# R7KA8D2AD register map
Vendor: Renesas Electronics Corporation; Series: RA8; File version: 1.10.02
CPU: CM85 r0p2, little endian, MPU, FPU, VTOR, 4 interrupt priority bits, 96 interrupts
Registers are 32-bit, read-write, reset 0x0 unless marked. A register's access mark holds for its fields unless they carry their own. Offsets are from the block's base; [hi:lo] are bit positions; 'fields as' and 'values as' point back to an identical list.

## I3C (part 1 of 2) — I3C Bus Interface
Base 0x4035F000
0x00 PRTS reset 0x1 — Protocol Selection Register
  [0] PRTMD — Protocol Mode
    0=I3C protocol mode; 1=I2C protocol mode
0x10 CECTL — Clock Enable Control Resister
  [0] CLKE — Clock Enable
    0=Clock disable; 1=Clock enable
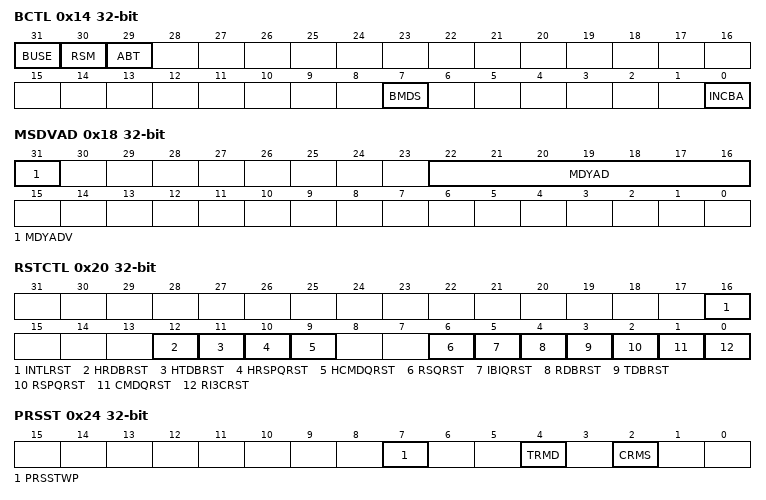
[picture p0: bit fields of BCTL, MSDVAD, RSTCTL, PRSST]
0x14 BCTL — Bus Control Register
  [31] BUSE — Bus Enable
    0=I3C bus operation is disabled; 1=I3C bus operation is enabled
  [30] RSM — Resume
    0=I3C is running; 1=I3C is suspended
  [29] ABT — Abort
    0=I3C is running; 1=I3C has aborted a transfer
  [7] BMDS — Bus Mode Selection
    0=Legacy inclusive Bus mode disabled; 1=Legacy inclusive (mix) Bus mode enabled
  [0] INCBA — Include I3C Broadcast Address
    0=Do not include I3C broadcast address for private transfers; 1=Include I3C broadcast address for private transfers
0x18 MSDVAD — Master Device Address Register
  [31] MDYADV — Master Dynamic Address Valid
    0=The master dynamic address field is not valid; 1=The master dynamic address field is valid
  [22:16] MDYAD — Master Dynamic Address
0x20 RSTCTL — Reset Control Register
  [16] INTLRST — Internal Software Reset
    0=Releases of some registers and internal state; 1=Resets of some registers and internal state
  [12] HRDBRST — High Priority Rx Data Buffer Software Reset
    0=The High Priority Rx Data buffers in I3C is not flushed; 1=The High Priority Rx Data buffers in I3C is flushed
  [11] HTDBRST — High Priority Tx Data Buffer Software Reset
    0=The High Priority Tx Data buffers in I3C is not flushed; 1=The High Priority Tx Data buffers in I3C is flushed
  [10] HRSPQRST — High Priority Response Queue Software Reset
    0=The High Priority Response Queues in I3C is not flushed; 1=The High Priority Response Queues in I3C is flushed
  [9] HCMDQRST — High Priority Command Queue Software Reset
    0=The High Priority Command Queues in I3C is not flushed; 1=The High Priority Command Queues in I3C is flushed
  [6] RSQRST — Normal Receive Status Queue Software Reset
    0=The Normal Receive Status Queue in I3C is not flushed; 1=The Normal Receive Status Queue in I3C is flushed
  [5] IBIQRST — Normal IBI Queue Software Reset
    0=The Normal IBI Queues in I3C is not flushed; 1=The Normal IBI Queues in I3C is flushed
  [4] RDBRST — Normal Rx Data Buffer Software Reset
    0=The Normal Rx Data buffers in I3C is not flushed; 1=The Normal Rx Data buffers in I3C is flushed
  [3] TDBRST — Normal Tx Data Buffer Software Reset
    0=The Normal Tx Data buffers in I3C is not flushed; 1=The Normal Tx Data buffers in I3C is flushed
  [2] RSPQRST — Normal Response Queue Software Reset
    0=The Normal Response Queues in I3C is not flushed; 1=The Normal Response Queues in I3C is flushed
  [1] CMDQRST — Normal Command Queue Software Reset
    0=The Normal Command Queues in I3C is not flushed; 1=The Normal Command Queues in I3C is flushed
  [0] RI3CRST — I3C Software Reset
    0=Release I3C reset; 1=Initiate I3C reset
0x24 PRSST — Present State Register
  [7] PRSSTWP wo — Present State Write Protect
    0=CRMS bit is protected; 1=CRMS bit can be written when writing simultaneously with the value of the target bit
  [4] TRMD ro — Transmit/Receive Mode
    0=Receive mode; 1=Transmit mode
  [2] CRMS — Current Master
    0=The Master is not the Current Master, and must request and acquire bus ownership before initiating any transfer; 1=The Master is the Current Master, and as a result can initiate transfers
0x30 INST — Internal Status Register
  [10] INEF — Internal Error Flag
    0=I3C Internal Error has not detected; 1=I3C Internal Error has detected
0x34 INSTE — Internal Status Enable Register
  [10] INEE — Internal Error Enable
    0=Disable INST.INEF; 1=Enable INST.INEF
0x38 INIE — Internal Interrupt Enable Register
  [10] INEIE — Internal Error Interrupt Enable
    0=Disables Non-recoverable Internal Error Interrupt Signal; 1=Enables Non-recoverable Internal Error Interrupt Signal
0x3C INSTFC wo — Internal Status Force Register
  [10] INEFC — Internal Error Force
    0=Not force a specific interrupt; 1=Force a specific interrupt
0x44 DVCT ro — Device Characteristic Table Register
  [23:19] IDX — DCT Table Index
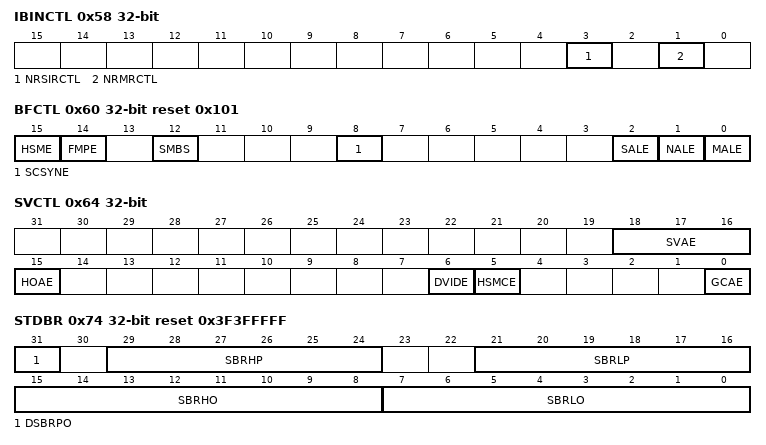
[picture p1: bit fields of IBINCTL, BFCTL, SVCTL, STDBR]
0x58 IBINCTL — IBI Notify Control Register
  [3] NRSIRCTL — Notify Rejected Slave Interrupt Request Control
    0=Do not pass rejected IBI Status to the Normal IBI Queue, if the incoming SIR is NACKed and is auto-disabled based on DVSIRRJ field in relevant DAT entry; 1=Pass rejected IBI Status to the Normal IBI Queue, if the incoming SIR is NACKed and is auto-disabled based on DVSIRRJ field in relevant DAT entry
  [1] NRMRCTL — Notify Rejected Master Request Control
    0=Do not pass rejected IBI Status to the Normal IBI Queue, if the incoming Master Request is NACKed and is auto-disabled based on DVMRRJ field in relevant DAT entry; 1=Pass rejected IBI Status to the Normal IBI Queue if the incoming Master Request is NACKed and is auto-disabled based on DVMRRJ field in relevant DAT entry
0x60 BFCTL reset 0x101 — Bus Function Control Register
  [15] HSME — High Speed Mode Enable
    0=Disable High Speed Mode; 1=Enable High Speed Mode
  [14] FMPE — Fast-mode Plus Enable
    0=No Fm+ slope control circuit uses for the I3C_SCL pin and I3C_SDA pin. (n = 0); 1=An Fm+ slope control circuit uses for the I3C_SCL pin and I3C_SDA pin. (n = 0)
  [12] SMBS — SMBus/I2C Bus Selection
    0=The I2C bus select; 1=The SMBus select
  [8] SCSYNE — SCL Synchronous Circuit Enable
    0=No SCL synchronous circuit uses; 1=An SCL synchronous circuit uses
  [2] SALE — Slave Arbitration-Lost Detection Enable
    0=Slave arbitration-lost detection disables; 1=Slave arbitration-lost detection enables
  [1] NALE — NACK Transmission Arbitration-Lost Detection Enable
    0=NACK transmission arbitration-lost detection disables; 1=NACK transmission arbitration-lost detection enables
  [0] MALE — Master Arbitration-Lost Detection Enable
    0=Master arbitration-lost detection disables. Disables the arbitration-lost detection function and does not clear the CRMS and TRMD bits in PRSST automatically when arbitration is lost.; 1=Master arbitration-lost detection enables. Enables the arbitration-lost detection function and clears the CRMS and TRMD bits in PRSST automatically when arbitration is lost.
0x64 SVCTL — Slave Control Register
  [18:16] SVAE — Slave Address Enable n ( n = 0 to 2 )
    0=Slave n disables; 1=Slave n enables
  [15] HOAE — Host Address Enable
    0=Host address detection disables; 1=Host address detection enables
  [6] DVIDE — Device-ID Address Enable
    0=Device-ID address detection disables; 1=Device-ID address detection enables
  [5] HSMCE — Hs-mode Master Code Enable
    0=Hs-mode Master Code Detection disables; 1=Hs-mode Master Code Detection enables
  [0] GCAE — General Call Address Enable
    0=General call address detection disables; 1=General call address detection enables
0x70 REFCKCTL — Reference Clock Control Register
  [2:0] IREFCKS — Internal Reference Clock Selection
    0=TCLK/1 clock; 1=TCLK/2 clock; 2=TCLK/4 clock; 3=TCLK/8 clock; 4=TCLK/16 clock; 5=TCLK/32 clock; 6=TCLK/64 clock; 7=TCLK/128 clock
0x74 STDBR reset 0x3F3FFFFF — Standard Bit Rate Register
  [31] DSBRPO — Double the Standard Bit Rate Period for Open-Drain
    0=The time period set for SBRHO[7:0] and SBRLO[7:0] is not doubled; 1=The time period set for SBRHO[7:0] and SBRLO[7:0] is doubled
  [29:24] SBRHP — Standard Bit Rate High-Level Period Push-Pull
  [21:16] SBRLP — Standard Bit Rate Low-level Period Push-Pull
  [15:8] SBRHO — Standard Bit Rate High-Level Period Open-Drain
  [7:0] SBRLO — Standard Bit Rate Low-Level Period Open-Drain
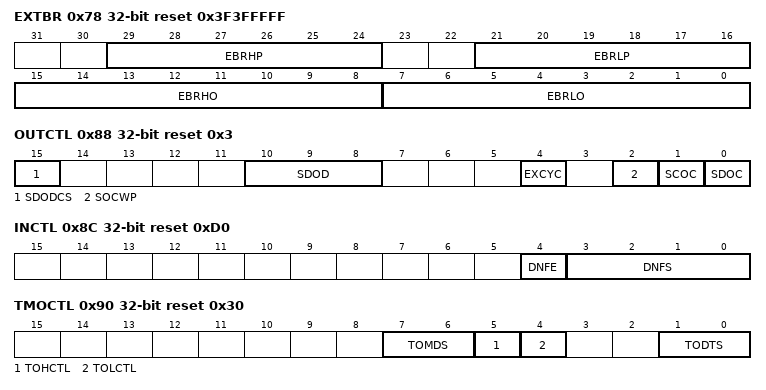
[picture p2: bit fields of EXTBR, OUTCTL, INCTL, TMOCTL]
0x78 EXTBR reset 0x3F3FFFFF — Extended Bit Rate Register
  [29:24] EBRHP — Extended Bit Rate High-Level Period Push-Pull
  [21:16] EBRLP — Extended Bit Rate Low-Level Period Push-Pull
  [15:8] EBRHO — Extended Bit Rate High-Level Period Open-Drain
  [7:0] EBRLO — Extended Bit Rate Low-Level Period Open-Drain
0x7C BFRECDT — Bus Free Condition Detection Time Register
  [8:0] FRECYC — Bus Free Condition Detection Cycle
0x80 BAVLCDT — Bus Available Condition Detection Time Register
  [8:0] AVLCYC — Bus Available Condition Detection Cycle
0x84 BIDLCDT — Bus Idle Condition Detection Time Register
  [17:0] IDLCYC — Bus Idle Condition Detection Cycle
0x88 OUTCTL reset 0x3 — Output Control Register
  [15] SDODCS — SDA Output Delay Clock Source Selection
    0=The internal reference clock (I3Cφ) is selected as the clock source of the SDA output delay counter; 1=The internal reference clock divided by 2 (I3Cφ/2) is selected as the clock source of the SDA output delay counter
  [10:8] SDOD — SDA Output Delay
    0=No output delay; 1=1 I3Cφ cycle (When OUTCTL.SDODCS = 0 (I3Cφ)) 1 or 2 I3Cφ cycles (When OUTCTL.SDODCS = 1 (I3Cφ/2)); 2=2 I3Cφ cycles (When OUTCTL.SDODCS = 0 (I3Cφ)) 3 or 4 I3Cφ cycles (When OUTCTL.SDODCS = 1 (I3Cφ/2)); 3=3 I3Cφ cycles (When OUTCTL.SDODCS = 0 (I3Cφ)) 5 or 6 I3Cφ cycles (When OUTCTL.SDODCS = 1 (I3Cφ/2)); 4=4 I3Cφ cycles (When OUTCTL.SDODCS = 0 (I3Cφ)) 7 or 8 I3Cφ cycles (When OUTCTL.SDODCS = 1 (I3Cφ/2)); 5=5 I3Cφ cycles (When OUTCTL.SDODCS = 0 (I3Cφ)) 9 or 10 I3Cφ cycles (When OUTCTL.SDODCS = 1 (I3Cφ/2)); 6=6 I3Cφ cycles (When OUTCTL.SDODCS = 0 (I3Cφ)) 11 or 12 I3Cφ cycles (When OUTCTL.SDODCS = 1 (I3Cφ/2)); 7=7 I3Cφ cycles (When OUTCTL.SDODCS = 0 (I3Cφ)) 13 or 14 I3Cφ cycles (When OUTCTL.SDODCS = 1 (I3Cφ/2))
  [4] EXCYC — Extra SCL Clock Cycle Output
    0=Does not output an extra SCL clock cycle (default); 1=Outputs an extra SCL clock cycle
  [2] SOCWP wo — SCL/SDA Output Control Write Protect
    0=Bits SCOC and SDOC are protected; 1=Bits SCOC and SDOC can be written (When writing simultaneously with the value of the target bit). This bit is read as 0.
  [1] SCOC — SCL Output Control
    0=I3C drives the I3C_SCL pin low; 1=I3C releases the I3C_SCL pin
  [0] SDOC — SDA Output Control
    0=I3C drives the I3C_SDA pin low; 1=I3C releases the I3C_SDA pin
0x8C INCTL reset 0xD0 — Input Control Register
  [4] DNFE — Digital Noise Filter Circuit Enable
    0=No digital noise filter circuit is used; 1=A digital noise filter circuit is used
  [3:0] DNFS — Digital Noise Filter Stage Selection
0x90 TMOCTL reset 0x30 — Timeout Control Register
  [7:6] TOMDS — Timeout Operation Mode Selection
    0=Timeout is detected during the following conditions: The bus is busy (BCST.BFREF = 0) in master mode.I3C’s own slave address is detected and the bus is busy in slave mode.The bus is free (BCST.BFREF = 1) while generation of a START condition is requested (CNDCTL.STCND = 1); 1=Timeout is detected while the bus is busy; 2=Timeout is detected while the bus is free; 3=Setting prohibited
  [5] TOHCTL — Timeout H Count Control
    0=Count is disabled while the I3C_SCL line is at a high level; 1=Count is enabled while the I3C_SCL line is at a high level
  [4] TOLCTL — Timeout L Count Control
    0=Count is disabled while the I3C_SCL line is at a low level; 1=Count is enabled while the I3C_SCL line is at a low level
  [1:0] TODTS — Timeout Detection Time Selection
    0=16bit-timeout; 1=14bit-timeout; 2=8bit-timeout; 3=6bit-timeout
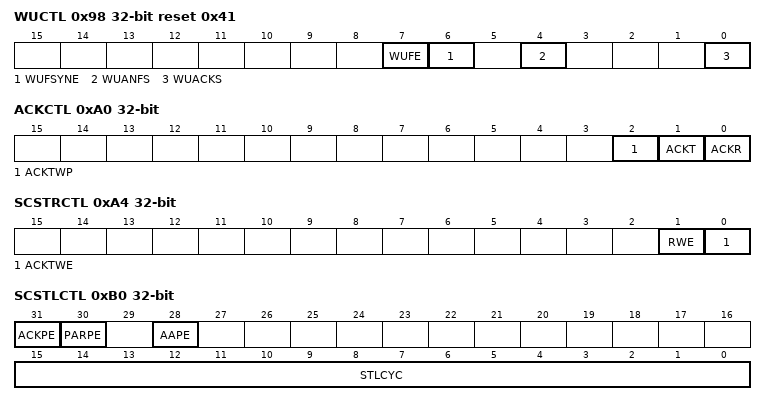
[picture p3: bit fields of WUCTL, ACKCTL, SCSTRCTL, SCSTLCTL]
0x98 WUCTL reset 0x41 — Wake Up Unit Control Register
  [7] WUFE — Wake-Up function Enable
    0=Wake-up function disables; 1=Wake-up function enables
  [6] WUFSYNE — Wake-Up function PCLK Synchronous Enable
    0=I3C asynchronous circuit enable; 1=I3C synchronous circuit enable
  [4] WUANFS — Wake-Up Analog Noise Filter Selection
    0=Do not add the Wake Up analog filter; 1=Add the Wake Up analog filter
  [0] WUACKS — Wake-Up Acknowledge Selection
0xA0 ACKCTL — Acknowledge Control Register
  [2] ACKTWP wo — ACKT Write Protect
    0=The ACKT bit are protected; 1=The ACKT bit can be written (when writing simultaneously with the value of the target bit). This bit is read as 0.
  [1] ACKT — Acknowledge Transmission
    0=A 0 is sent as the acknowledge bit (ACK transmission); 1=A 1 is sent as the acknowledge bit (NACK transmission)
  [0] ACKR ro — Acknowledge Reception
    0=A 0 is received as the acknowledge bit (ACK reception); 1=A 1 is received as the acknowledge bit (NACK reception)
0xA4 SCSTRCTL — SCL Stretch Control Register
  [1] RWE — Receive Wait Enable
    0=No WAIT (The period between ninth clock cycle and first clock cycle is not held low.); 1=WAIT (The period between ninth clock cycle and first clock cycle is held low.) Low-hold is released by reading NTDTBP0
  [0] ACKTWE — Acknowledge Transmission Wait Enable
    0=NTST.RDBFF0 is set at the rising edge of the ninth SCL clock cycle. (The I3C_SCL line is not held low at the falling edge of the eighth clock cycle.); 1=NTST.RDBFF0 is set at the rising edge of the eighth SCL clock cycle. (The I3C_SCL line is held low at the falling edge of the eighth clock cycle.) Low-hold is released by writing a value to the ACKCTL.ACKT bit.
0xB0 SCSTLCTL — SCL Stalling Control Register
  [31] ACKPE — ACK phase Enable
    0=Does not stall the SCL clock during the ACK/NACK phase; 1=Stall the SCL clock during the ACK/NACK phase
  [30] PARPE — Parity Phase Enable
    0=Does not stall the SCL clock during the parity bit period; 1=Stall the SCL clock during the parity bit period
  [28] AAPE — Assigned Address Phase Enable
    0=Does not stall the SCL clock during the address assignment phase; 1=Stall the SCL clock during address assignment phase
  [15:0] STLCYC — Stalling Cycle
0xC0 SVTDLG0 — Slave Transfer Data Length Register 0
  [31:16] STDLG — Slave Transfer Data Length
0x120 STCTL — Synchronous Timing Control Register
  [0] STOE — Synchronous Timing output Enable
    0=Disable; 1=Enable
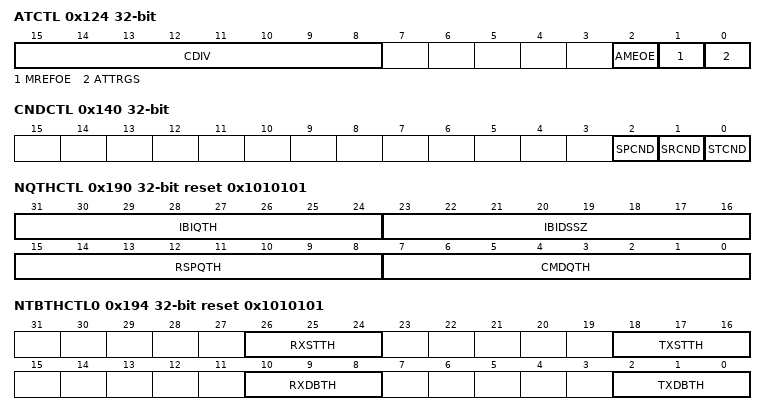
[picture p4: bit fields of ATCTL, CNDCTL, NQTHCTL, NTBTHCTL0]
0x124 ATCTL — Asynchronous Timing Control Register
  [15:8] CDIV — TCLK Counter Divide Setting
  [2] AMEOE — Additional Master-initiated bus Event Output Enable
    0=Disable; 1=Enable
  [1] MREFOE — MREF Output Enable (Capture Event / Counter Overflow)
    0=Disable; 1=Enable
  [0] ATTRGS — Asynchronous Timing Trigger Select
    0=Software trigger; 1=Hardware trigger
0x128 ATTRG — Asynchronous Timing Trigger Register
  [0] ATSTRG wo — Asynchronous Timing Software Trigger
    0=Do nothing; 1=Software trigger (one-shot pulse) output This bit is always read as 0
0x12C ATCCNTE — Asynchronous Timing Control Counter Enable Register
  [0] ATCE — Asynchronous Timing Counter Enable for MREF, MC2, SC1, SC2.
    0=Disable; 1=Enable
0x140 CNDCTL — Condition Control Register
  [2] SPCND — STOP (P) Condition Issuance
    0=Does not request to issue a STOP condition; 1=Requests to issue a STOP condition
  [1] SRCND — Repeated START (Sr) Condition Issuance
    0=Does not request to issue a Repeated START condition; 1=Requests to issue a Repeated START condition
  [0] STCND — START (S) Condition Issuance
    0=Does not request to issue a START condition; 1=Requests to issue a START condition
0x150 NCMDQP wo — Normal Command Queue Port Register
0x154 NRSPQP ro — Normal Response Queue Port Register
0x158 NTDTBP0 — Normal Transfer Data Buffer Port Register 0
0x158 NTDTBP0_BY 8-bit (alternate view of NTDTBP0) — Normal Transfer Data Buffer Port Register 0
0x17C NIBIQP — Normal IBI Queue Port Register
0x180 NRSQP ro — Normal Receive Status Queue Port Register
0x184 HCMDQP wo — High Priority Command Queue Port Register
0x188 HRSPQP ro — High Priority Response Queue Port Register
0x18C HTDTBP — High Priority Transfer Data Buffer Port Register
0x190 NQTHCTL reset 0x1010101 — Normal Queue Threshold Control Register
  [31:24] IBIQTH — Normal IBI Queue Threshold
    0=I3C Protocol mode (Master): Interrupt is generated when the Outstanding IBI Status count is 1 or more. I3C Protocol mode (Slave): Interrupt is issued when IBI Data Buffer is completely empty.; other=Others (I3C Protocol mode (Master): Interrupt is generated when the Outstanding IBI Status count is N + 1 or more. (N = CMDQTH[7:0]) I3C Protocol mode (Slave): Interrupt is issued when IBI Data Buffer contains N empties.)
  [23:16] IBIDSSZ — Normal IBI Data Segment Size
  [15:8] RSPQTH — Normal Response Queue Threshold
    0=Interrupt is issued when Normal Response Queue contains 1 entry (DWORD); other=Others (Interrupt is triggered when Normal Response Queue contains N+1 entries (DWORD). (N = CMDQTH[7:0]))
  [7:0] CMDQTH — Normal Command Queue Threshold
    0=Interrupt is issued when Normal Command Queue is completely empty; other=Others (Interrupt is issued when Normal Command Queue contains N empties. (N = CMDQTH[7:0]))
0x194 NTBTHCTL0 reset 0x1010101 — Normal Transfer Data Buffer Threshold Control Register 0
  [26:24] RXSTTH — Normal Rx Start Threshold
    0=Wait for 2 empty DWORDs; 1=Wait for 4 empty DWORDs; 2=Wait for 8 empty DWORDs; 3=Wait for 16 empty DWORDs; other=Others (Setting prohibited)
  [18:16] TXSTTH — Normal Tx Start Threshold
    0=Wait for 2 entry DWORDs; 1=Wait for 4 entry DWORDs; 2=Wait for 8 entry DWORDs; 3=Wait for 16 entry DWORDs; other=Others (Setting prohibited)
  [10:8] RXDBTH — Normal Rx Data Buffer Threshold
    0=Interrupt triggers at 2 Rx Buffer entries, DWORDs; 1=Interrupt triggers at 4 Rx Buffer entries, DWORDs; 2=Interrupt triggers at 8 Rx Buffer entries, DWORDs; 3=Interrupt triggers at 16 Rx Buffer entries, DWORDs; other=Others (Setting prohibited)
  [2:0] TXDBTH — Normal Tx Data Buffer Threshold
    0=Interrupt triggers at 2 Tx Buffer empties, DWORDs; 1=Interrupt triggers at 4 Tx Buffer empties, DWORDs; 2=Interrupt triggers at 8 Tx Buffer empties, DWORDs; 3=Interrupt triggers at 16 Tx Buffer empties, DWORDs; other=Others (Setting prohibited)
0x1C0 NRQTHCTL reset 0x1 — Normal Receive Status Queue Threshold Control Register
  [7:0] RSQTH — Normal Receive Status Queue Threshold
    0=Interrupt is issued when Normal Receive Status Queue contains 1 entry (DWORD); other=Others (Interrupt is triggered when Normal Receive Status Queue contains N+1 entries (DWORD). (N = RSQTH[7:0]))
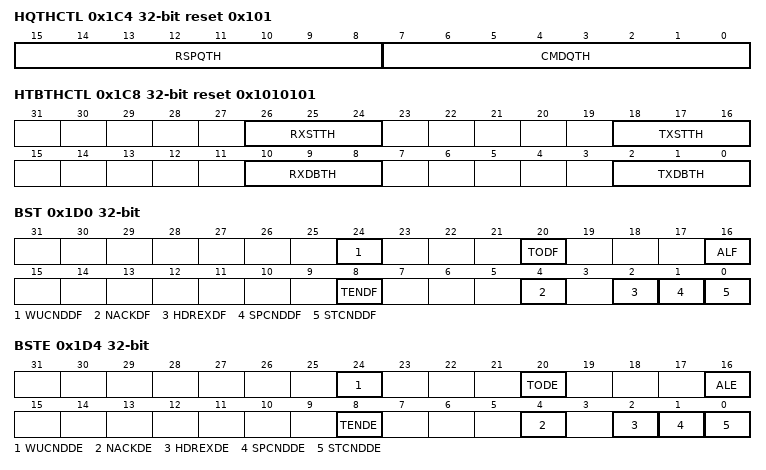
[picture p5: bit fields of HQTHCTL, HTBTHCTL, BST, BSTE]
0x1C4 HQTHCTL reset 0x101 — High Priority Queue Threshold Control Register
  [15:8] RSPQTH — High Priority Response Queue Threshold
    0=Interrupt is issued when High Priority Response Queue contains 1 entry (DWORD); other=Others (Interrupt is triggered when High Priority Response Queue contains N+1 entries (DWORD). (N = RSPQTH[7:0]))
  [7:0] CMDQTH — High Priority Command Queue Threshold
    0=Interrupt is issued when High Priority Command Queue is completely empty; other=Others (Interrupt is issued when High Priority Command Queue contains N entries. (N = CMDQTH[7:0]))
0x1C8 HTBTHCTL reset 0x1010101 — High Priority Transfer Data Buffer Threshold Control Register
  [26:24] RXSTTH — High Priority Rx Start Threshold
    0=Wait for 2 empty DWORDs; other=Others (Setting prohibited)
  [18:16] TXSTTH — High Priority Tx Start Threshold
    0=Wait for 2 entry DWORDs; other=Others (Setting prohibited)
  [10:8] RXDBTH — High Priority Rx Data Buffer Threshold
    0=Interrupt triggers at 2 High Priority Rx Buffer entries, DWORDs; other=Others (Setting prohibited)
  [2:0] TXDBTH — High Priority Tx Data Buffer Threshold
    0=Interrupt triggers at 2 High Priority Tx Buffer empties, DWORDs; other=Others (Setting prohibited)
0x1D0 BST — Bus Status Register
  [24] WUCNDDF — Wake-Up Condition Detection Flag
    0=Wake-Up is not detected; 1=Wake-Up is detected
  [20] TODF — Timeout Detection Flag
    0=Timeout is not detected; 1=Timeout is detected
  [16] ALF — Arbitration Lost Flag
    0=Arbitration is not lost; 1=Arbitration is lost
  [8] TENDF — Transmit End Flag
    0=Data is being transmitted; 1=Data has been transmitted
  [4] NACKDF — NACK Detection Flag
    0=NACK is not detected; 1=NACK is detected
  [2] HDREXDF — HDR Exit Pattern Detection Flag
    0=HDR Exit Pattern is not detected; 1=HDR Exit Pattern is detected
  [1] SPCNDDF — STOP Condition Detection Flag
    0=STOP condition is not detected; 1=STOP condition is detected
  [0] STCNDDF — START Condition Detection Flag
    0=START condition is not detected; 1=START condition is detected
0x1D4 BSTE — Bus Status Enable Register
  [24] WUCNDDE — Wake-up Condition Detection Enable
    0=Disables Wake-up Condition Detection Status logging; 1=Enables Wake-up Condition Detection Status logging
  [20] TODE — Timeout Detection Enable
    0=Disables Timeout Detection Interrupt Status logging; 1=Enables Timeout Detection Interrupt Status logging
  [16] ALE — Arbitration Lost Enable
    0=Disables Arbitration Lost Interrupt Status logging; 1=Enables Arbitration Lost Interrupt Status logging
  [8] TENDE — Transmit End Enable
    0=Disables Transmit End Interrupt Status logging; 1=Enables Transmit End Interrupt Status logging
  [4] NACKDE — NACK Detection Enable
    0=Disables NACK Detection Interrupt Status logging; 1=Enables NACK Detection Interrupt Status logging
  [2] HDREXDE — HDR Exit Pattern Detection Enable
    0=Disables HDR Exit Pattern Detection Interrupt Status logging; 1=Enables HDR Exit Pattern Detection Interrupt Status logging
  [1] SPCNDDE — STOP Condition Detection Enable
    0=Disables STOP condition Detection Interrupt Status logging; 1=Enables STOP condition Detection Interrupt Status logging
  [0] STCNDDE — START Condition Detection Enable
    0=Disables START condition Detection Interrupt Status logging; 1=Enables START condition Detection Interrupt Status logging
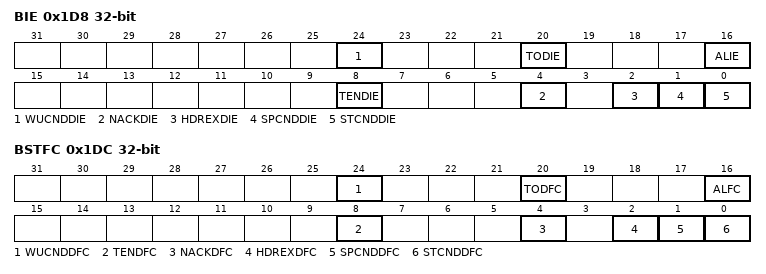
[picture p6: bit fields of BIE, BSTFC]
0x1D8 BIE — Bus Interrupt Enable Register
  [24] WUCNDDIE — Wake-Up Condition Detection Interrupt Enable
    0=Disables Wake-Up Condition Detection Interrupt Signal; 1=Enables Wake-Up Condition Detection Interrupt Signal
  [20] TODIE — Timeout Detection Interrupt Enable
    0=Disables Timeout Detection Interrupt Signal; 1=Enables Timeout Detection Interrupt Signal
  [16] ALIE — Arbitration Lost Interrupt Enable
    0=Disables Arbitration Lost Interrupt Signal; 1=Enables Arbitration Lost Interrupt Signal
  [8] TENDIE — Transmit End Interrupt Enable
    0=Disables Transmit End Interrupt Signal; 1=Enables Transmit End Interrupt Signal
  [4] NACKDIE — NACK Detection Interrupt Enable
    0=Disables NACK Detection Interrupt Signal; 1=Enables NACK Detection Interrupt Signal
  [2] HDREXDIE — HDR Exit Pattern Detection Interrupt Enable
    0=Disables HDR Exit Pattern Detection Interrupt Signal; 1=Enables HDR Exit Pattern Detection Interrupt Signal
  [1] SPCNDDIE — STOP Condition Detection Interrupt Enable
    0=Disables STOP condition Detection Interrupt Signal; 1=Enables STOP condition Detection Interrupt Signal
  [0] STCNDDIE — START Condition Detection Interrupt Enable
    0=Disables START condition Detection Interrupt Signal; 1=Enables START condition Detection Interrupt Signal
0x1DC BSTFC — Bus Status Force Register
  [24] WUCNDDFC wo — Wake-Up Condition Detection Force
    0=Not Force Wake-Up Condition Detection Interrupt for software testing; 1=Force Wake-Up Condition Detection Interrupt for software testing
  [20] TODFC wo — Timeout Detection Force
    0=Not Force Timeout Detection Interrupt for software testing; 1=Force Timeout Detection Interrupt for software testing
  [16] ALFC wo — Arbitration Lost Force
    0=Not Force Arbitration Lost Interrupt for software testing; 1=Force Arbitration Lost Interrupt for software testing
  [8] TENDFC wo — Transmit End Force
    0=Not Force Transmit End Interrupt for software testing; 1=Force Transmit End Interrupt for software testing
  [4] NACKDFC wo — NACK Detection Force
    0=Not Force NACK Detection Interrupt for software testing; 1=Force NACK Detection Interrupt for software testing
  [2] HDREXDFC wo — HDR Exit Pattern Detection Force
    0=Not Force HDR Exit Pattern Detection Interrupt for software testing; 1=Force HDR Exit Pattern Detection Interrupt for software testing
  [1] SPCNDDFC wo — STOP condition Detection Force
    0=Not Force STOP condition Detection Interrupt for software testing; 1=Force STOP condition Detection Interrupt for software testing
  [0] STCNDDFC wo — START condition Detection Force
    0=Not Force START condition Detection Interrupt for software testing; 1=Force START condition Detection Interrupt for software testing

## I3C_NS (part 1 of 2) — I3C Bus Interface
Base 0x5035F000
Registers as I3C; these are added or differ:
0x00 PRTS reset 0x1 — Protocol Selection Register
  [0] PRTMD — Protocol Mode
    0=I3C protocol mode; 1=I2C protocol mode
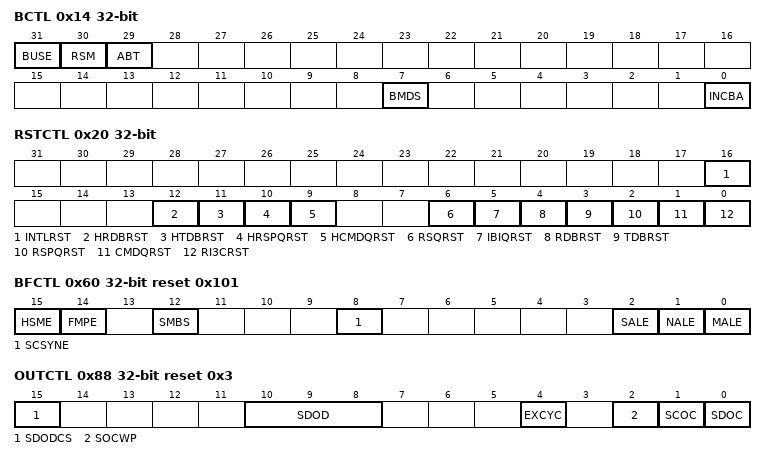
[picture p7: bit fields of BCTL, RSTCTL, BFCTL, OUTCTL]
0x14 BCTL — Bus Control Register
  fields as I3C.BCTL
0x20 RSTCTL — Reset Control Register
  fields as I3C.RSTCTL
0x30 INST — Internal Status Register
  [10] INEF — Internal Error Flag
    0=I3C Internal Error has not detected; 1=I3C Internal Error has detected
0x60 BFCTL reset 0x101 — Bus Function Control Register
  fields as I3C.BFCTL
0x88 OUTCTL reset 0x3 — Output Control Register
  fields as I3C.OUTCTL
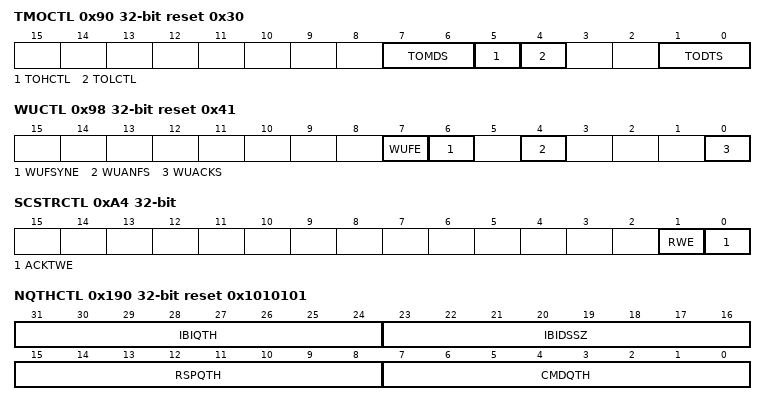
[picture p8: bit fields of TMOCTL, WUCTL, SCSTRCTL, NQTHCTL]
0x90 TMOCTL reset 0x30 — Timeout Control Register
  fields as I3C.TMOCTL
0x98 WUCTL reset 0x41 — Wake Up Unit Control Register
  fields as I3C.WUCTL
0xA4 SCSTRCTL — SCL Stretch Control Register
  fields as I3C.SCSTRCTL
0x190 NQTHCTL reset 0x1010101 — Normal Queue Threshold Control Register
  fields as I3C.NQTHCTL
